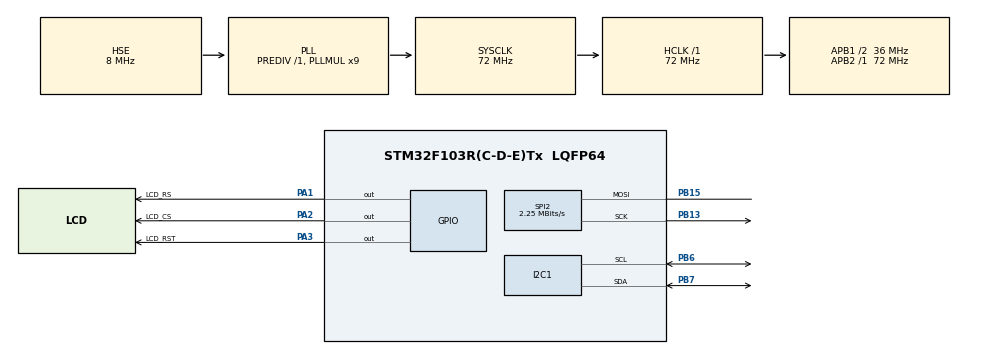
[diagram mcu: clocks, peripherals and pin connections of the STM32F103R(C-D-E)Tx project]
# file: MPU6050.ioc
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Mcu.Family=STM32F1
Mcu.Name=STM32F103R(C-D-E)Tx
Mcu.Package=LQFP64
NVIC.PriorityGroup=NVIC_PRIORITYGROUP_4
PA1.GPIO_Label=LCD_RS
PA1.Signal=GPIO_Output
PA13.Mode=Serial_Wire
PA13.Signal=SYS_JTMS-SWDIO
PA14.Mode=Serial_Wire
PA14.Signal=SYS_JTCK-SWCLK
PA2.GPIO_Label=LCD_CS
PA2.Signal=GPIO_Output
PA3.GPIO_Label=LCD_RST
PA3.Signal=GPIO_Output
PB13.Mode=Simplex_Bidirectional_Master
PB13.Signal=SPI2_SCK
PB15.Mode=Simplex_Bidirectional_Master
PB15.Signal=SPI2_MOSI
PB6.Mode=I2C
PB6.Signal=I2C1_SCL
PB7.Mode=I2C
PB7.Signal=I2C1_SDA
PD0-OSC_IN.Mode=HSE-External-Oscillator
PD0-OSC_IN.Signal=RCC_OSC_IN
PD1-OSC_OUT.Mode=HSE-External-Oscillator
PD1-OSC_OUT.Signal=RCC_OSC_OUT
ProjectManager.HeapSize=0x200
ProjectManager.StackSize=0x400
ProjectManager.TargetToolchain=STM32CubeIDE
RCC.AHBFreq_Value=72000000
RCC.APB1CLKDivider=RCC_HCLK_DIV2
RCC.APB1Freq_Value=36000000
RCC.APB1TimFreq_Value=72000000
RCC.APB2Freq_Value=72000000
RCC.APB2TimFreq_Value=72000000
RCC.HCLKFreq_Value=72000000
RCC.PLLMUL=RCC_PLL_MUL9
RCC.PLLSourceVirtual=RCC_PLLSOURCE_HSE
RCC.SYSCLKFreq_VALUE=72000000
RCC.SYSCLKSource=RCC_SYSCLKSOURCE_PLLCLK
RCC.USBFreq_Value=72000000
SPI2.BaudRatePrescaler=SPI_BAUDRATEPRESCALER_16
SPI2.CalculateBaudRate=2.25 MBits/s
SPI2.Direction=SPI_DIRECTION_1LINE
SPI2.Mode=SPI_MODE_MASTER
SPI2.VirtualType=VM_MASTER
board=custom

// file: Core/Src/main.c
/* USER CODE BEGIN Header */
/**
  ******************************************************************************
  * @file           : main.c
  * @brief          : Main program body
  ******************************************************************************
  * @attention
  *
  * Copyright (c) 2024 STMicroelectronics.
  * All rights reserved.
  *
  * This software is licensed under terms that can be found in the LICENSE file
  * in the root directory of this software component.
  * If no LICENSE file comes with this software, it is provided AS-IS.
  *
  ******************************************************************************
  */
/* USER CODE END Header */
#include "main.h"
#include "mpu6050.h"
#include "ILI9225.h"
#include "stdio.h"
/* USER CODE BEGIN Includes */

// Các biến để lưu vị trí thông số
#define AX_X 5
#define AX_Y 40
#define AY_Y 60
#define AZ_Y 80
#define GX_X 110
#define GX_Y 40
#define GY_Y 60
#define GZ_Y 80

I2C_HandleTypeDef hi2c1;

SPI_HandleTypeDef hspi2;

void SystemClock_Config(void);
static void MX_GPIO_Init(void);
static void MX_I2C1_Init(void);
static void MX_SPI2_Init(void);

/* USER CODE BEGIN 0 */
char buf[4];

MPU6050_t MPU6050;

/* USER CODE END 0 */

int main(void)
{

  /* MCU Configuration--------------------------------------------------------*/

  /* Reset of all peripherals, Initializes the Flash interface and the Systick. */
  HAL_Init();

  /* Configure the system clock */
  SystemClock_Config();

  /* Initialize all configured peripherals */
  MX_GPIO_Init();
  MX_I2C1_Init();
  MX_SPI2_Init();
  /* USER CODE BEGIN 2 */

  lcd_init();
  fill_rectangle(0, 0, WIDTH, HEIGHT, COLOR_BLACK );
  /* USER CODE END 2 */
  MPU6050_Init(&hi2c1);
  /* Infinite loop */
  while (1)
  {
	  MPU6050_Read_Accel(&hi2c1, &MPU6050);
	  MPU6050_Read_Gyro(&hi2c1, &MPU6050);

	   // Lưu thông số mới
	    float new_AX = MPU6050.Ax;
	    float new_AY = MPU6050.Ay;
	    float new_AZ = MPU6050.Az;

	    float new_GX = MPU6050.Gx;
	    float new_GY = MPU6050.Gy;
	    float new_GZ = MPU6050.Gz;

	    // Xóa các ký tự cũ bằng cách vẽ lại màu nền
	    fill_rectangle(AX_X + 27.5, AX_Y , 100, 50, COLOR_BLACK); // Xóa AX
	    fill_rectangle(AX_X + 27.5, AY_Y , 100, 70, COLOR_BLACK); // Xóa AY
	    fill_rectangle(AX_X + 27.5, AZ_Y , 100, 90, COLOR_BLACK); // Xóa AZ
	    fill_rectangle(GX_X + 27.5, GX_Y , 200, 50, COLOR_BLACK); // Xóa GX
	    fill_rectangle(GX_X + 27.5, GY_Y , 200, 70, COLOR_BLACK); // Xóa GY
	    fill_rectangle(GX_X + 27.5, GZ_Y , 200, 90, COLOR_BLACK); // Xóa GZ

	    // Vẽ lại các thông số mới
	    draw_string(AX_X,10,COLOR_RED,1.8,"ACCEL");
	    sprintf(buf, "AX=%.2f", new_AX);
	    draw_string(AX_X, AX_Y, COLOR_YELLOW, 1.75, buf);

	    sprintf(buf, "AY=%.2f", new_AY);
	    draw_string(AX_X, AY_Y, COLOR_BLUE, 1.75, buf);

	    sprintf(buf, "AZ=%.2f", new_AZ);
	    draw_string(AX_X, AZ_Y, COLOR_ORANGE, 1.75, buf);

	    draw_string(GX_X,10,COLOR_RED,1.8,"GYRO");
	    sprintf(buf, "GX=%.2f", new_GX);
	    draw_string(GX_X, GX_Y, COLOR_YELLOW, 1.75, buf);

	    sprintf(buf, "GY=%.2f", new_GY);
	    draw_string(GX_X, GY_Y, COLOR_BLUE, 1.75, buf);

	    sprintf(buf, "GZ=%.2f", new_GZ);
	    draw_string(GX_X, GZ_Y, COLOR_ORANGE, 1.75, buf);

  }
  /* USER CODE END 3 */
}

void SystemClock_Config(void)
{
  RCC_OscInitTypeDef RCC_OscInitStruct = {0};
  RCC_ClkInitTypeDef RCC_ClkInitStruct = {0};

  /** Initializes the RCC Oscillators according to the specified parameters
  * in the RCC_OscInitTypeDef structure.
  */
  RCC_OscInitStruct.OscillatorType = RCC_OSCILLATORTYPE_HSE;
  RCC_OscInitStruct.HSEState = RCC_HSE_ON;
  RCC_OscInitStruct.HSEPredivValue = RCC_HSE_PREDIV_DIV1;
  RCC_OscInitStruct.HSIState = RCC_HSI_ON;
  RCC_OscInitStruct.PLL.PLLState = RCC_PLL_ON;
  RCC_OscInitStruct.PLL.PLLSource = RCC_PLLSOURCE_HSE;
  RCC_OscInitStruct.PLL.PLLMUL = RCC_PLL_MUL9;
  if (HAL_RCC_OscConfig(&RCC_OscInitStruct) != HAL_OK)
  {
    Error_Handler();
  }

  /** Initializes the CPU, AHB and APB buses clocks
  */
  RCC_ClkInitStruct.ClockType = RCC_CLOCKTYPE_HCLK|RCC_CLOCKTYPE_SYSCLK
                              |RCC_CLOCKTYPE_PCLK1|RCC_CLOCKTYPE_PCLK2;
  RCC_ClkInitStruct.SYSCLKSource = RCC_SYSCLKSOURCE_PLLCLK;
  RCC_ClkInitStruct.AHBCLKDivider = RCC_SYSCLK_DIV1;
  RCC_ClkInitStruct.APB1CLKDivider = RCC_HCLK_DIV2;
  RCC_ClkInitStruct.APB2CLKDivider = RCC_HCLK_DIV1;

  if (HAL_RCC_ClockConfig(&RCC_ClkInitStruct, FLASH_LATENCY_2) != HAL_OK)
  {
    Error_Handler();
  }
}

static void MX_I2C1_Init(void)
{

  hi2c1.Instance = I2C1;
  hi2c1.Init.ClockSpeed = 100000;
  hi2c1.Init.DutyCycle = I2C_DUTYCYCLE_2;
  hi2c1.Init.OwnAddress1 = 0;
  hi2c1.Init.AddressingMode = I2C_ADDRESSINGMODE_7BIT;
  hi2c1.Init.DualAddressMode = I2C_DUALADDRESS_DISABLE;
  hi2c1.Init.OwnAddress2 = 0;
  hi2c1.Init.GeneralCallMode = I2C_GENERALCALL_DISABLE;
  hi2c1.Init.NoStretchMode = I2C_NOSTRETCH_DISABLE;
  if (HAL_I2C_Init(&hi2c1) != HAL_OK)
  {
    Error_Handler();
  }

}

static void MX_SPI2_Init(void)
{

  /* SPI2 parameter configuration*/
  hspi2.Instance = SPI2;
  hspi2.Init.Mode = SPI_MODE_MASTER;
  hspi2.Init.Direction = SPI_DIRECTION_1LINE;
  hspi2.Init.DataSize = SPI_DATASIZE_8BIT;
  hspi2.Init.CLKPolarity = SPI_POLARITY_LOW;
  hspi2.Init.CLKPhase = SPI_PHASE_1EDGE;
  hspi2.Init.NSS = SPI_NSS_SOFT;
  hspi2.Init.BaudRatePrescaler = SPI_BAUDRATEPRESCALER_16;
  hspi2.Init.FirstBit = SPI_FIRSTBIT_MSB;
  hspi2.Init.TIMode = SPI_TIMODE_DISABLE;
  hspi2.Init.CRCCalculation = SPI_CRCCALCULATION_DISABLE;
  hspi2.Init.CRCPolynomial = 10;
  if (HAL_SPI_Init(&hspi2) != HAL_OK)
  {
    Error_Handler();
  }

}

static void MX_GPIO_Init(void)
{
  GPIO_InitTypeDef GPIO_InitStruct = {0};

  /* GPIO Ports Clock Enable */
  __HAL_RCC_GPIOD_CLK_ENABLE();
  __HAL_RCC_GPIOA_CLK_ENABLE();
  __HAL_RCC_GPIOB_CLK_ENABLE();

  /*Configure GPIO pin Output Level */
  HAL_GPIO_WritePin(GPIOA, LCD_RS_Pin|LCD_CS_Pin|LCD_RST_Pin, GPIO_PIN_RESET);

  /*Configure GPIO pins : LCD_RS_Pin LCD_CS_Pin LCD_RST_Pin */
  GPIO_InitStruct.Pin = LCD_RS_Pin|LCD_CS_Pin|LCD_RST_Pin;
  GPIO_InitStruct.Mode = GPIO_MODE_OUTPUT_PP;
  GPIO_InitStruct.Pull = GPIO_NOPULL;
  GPIO_InitStruct.Speed = GPIO_SPEED_FREQ_LOW;
  HAL_GPIO_Init(GPIOA, &GPIO_InitStruct);

}

void Error_Handler(void)
{
  __disable_irq();
  while (1)
  {
  }
}
